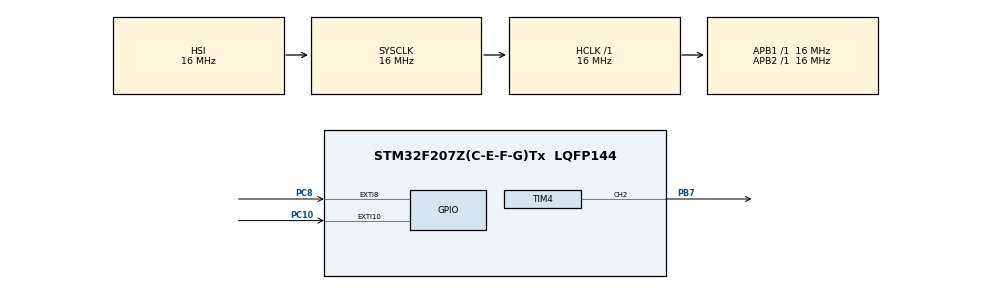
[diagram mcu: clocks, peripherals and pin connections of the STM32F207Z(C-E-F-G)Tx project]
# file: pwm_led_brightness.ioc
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Mcu.Family=STM32F2
Mcu.Name=STM32F207Z(C-E-F-G)Tx
Mcu.Package=LQFP144
NVIC.EXTI15_10_IRQn=true\:0\:0\:false\:false\:true\:true\:true\:true
NVIC.EXTI9_5_IRQn=true\:0\:0\:false\:false\:true\:true\:true\:true
NVIC.PriorityGroup=NVIC_PRIORITYGROUP_4
NVIC.TIM4_IRQn=true\:0\:0\:false\:false\:true\:true\:true\:true
PB7.Signal=S_TIM4_CH2
PC10.GPIO_ModeDefaultEXTI=GPIO_MODE_IT_FALLING
PC10.GPIO_PuPd=GPIO_PULLDOWN
PC10.Signal=GPXTI10
PC8.GPIO_ModeDefaultEXTI=GPIO_MODE_IT_FALLING
PC8.GPIO_PuPd=GPIO_PULLDOWN
PC8.Signal=GPXTI8
PH0-OSC_IN.Mode=HSE-External-Oscillator
PH0-OSC_IN.Signal=RCC_OSC_IN
PH1-OSC_OUT.Mode=HSE-External-Oscillator
PH1-OSC_OUT.Signal=RCC_OSC_OUT
ProjectManager.HeapSize=0x200
ProjectManager.StackSize=0x400
ProjectManager.TargetToolchain=STM32CubeIDE
RCC.48MHZClocksFreq_Value=48000000
RCC.AHBFreq_Value=16000000
RCC.APB1Freq_Value=16000000
RCC.APB2Freq_Value=16000000
RCC.CortexFreq_Value=16000000
RCC.HSE_VALUE=25000000
RCC.HSI_VALUE=16000000
RCC.LSE_VALUE=32768
RCC.SYSCLKFreq_VALUE=16000000
RCC.VCOOutputFreq_Value=192000000
SH.S_TIM4_CH2.0=TIM4_CH2,PWM Generation2 CH2
TIM4.AutoReloadPreload=TIM_AUTORELOAD_PRELOAD_DISABLE
TIM4.Channel-PWM\ Generation2\ CH2=TIM_CHANNEL_2
TIM4.Period=100 - 1
TIM4.Prescaler=1600 - 1
VP_TIM4_VS_ClockSourceINT.Mode=Internal
board=custom

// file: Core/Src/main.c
/* USER CODE BEGIN Header */
/**
  ******************************************************************************
  * @file           : main.c
  * @brief          : Main program body
  ******************************************************************************
  * @attention
  *
  * Copyright (c) 2023 STMicroelectronics.
  * All rights reserved.
  *
  * This software is licensed under terms that can be found in the LICENSE file
  * in the root directory of this software component.
  * If no LICENSE file comes with this software, it is provided AS-IS.
  *
  ******************************************************************************
  */
/* USER CODE END Header */
#include "main.h"

TIM_HandleTypeDef htim4;

/* USER CODE BEGIN PV */
static int pwmValue = 50;
/* USER CODE END PV */

void SystemClock_Config(void);
static void MX_GPIO_Init(void);
static void MX_TIM4_Init(void);

/* USER CODE BEGIN 0 */
void HAL_GPIO_EXTI_Callback(uint16_t GPIO_Pin)
{
	if (GPIO_Pin == GPIO_PIN_8)
	{
		HAL_TIM_PWM_Stop(&htim4, TIM_CHANNEL_2);
		pwmValue -= 5;
		if (pwmValue >= 0)
		{
		TIM4->CCR2 = pwmValue;
		HAL_TIM_PWM_Start(&htim4, TIM_CHANNEL_2);
		}
		else {
			pwmValue = 50;
			HAL_TIM_PWM_Start(&htim4, TIM_CHANNEL_2);
		}
	}
	if (GPIO_Pin == GPIO_PIN_10)
	{
		HAL_TIM_PWM_Stop(&htim4, TIM_CHANNEL_2);
		pwmValue += 5;
		if (pwmValue <= 100)
		{
		TIM4->CCR2 = pwmValue;
		HAL_TIM_PWM_Start(&htim4, TIM_CHANNEL_2);
		}
		else {
			pwmValue = 50;
			HAL_TIM_PWM_Start(&htim4, TIM_CHANNEL_2);
		}
	}
}
/* USER CODE END 0 */

int main(void)
{

  /* MCU Configuration--------------------------------------------------------*/

  /* Reset of all peripherals, Initializes the Flash interface and the Systick. */
  HAL_Init();

  /* Configure the system clock */
  SystemClock_Config();

  /* Initialize all configured peripherals */
  MX_GPIO_Init();
  MX_TIM4_Init();
  /* USER CODE BEGIN 2 */
  if (__HAL_TIM_GET_FLAG(&htim4, TIM_FLAG_UPDATE) != RESET)
	  __HAL_TIM_CLEAR_FLAG(&htim4, TIM_FLAG_UPDATE);
  HAL_TIM_Base_Start_IT(&htim4);
  TIM4->CCR2 = 50;
  HAL_TIM_PWM_Start(&htim4, TIM_CHANNEL_2);
  /* USER CODE END 2 */

  /* Infinite loop */
  while (1)
  {

  }
}

void SystemClock_Config(void)
{
  RCC_OscInitTypeDef RCC_OscInitStruct = {0};
  RCC_ClkInitTypeDef RCC_ClkInitStruct = {0};

  /** Initializes the RCC Oscillators according to the specified parameters
  * in the RCC_OscInitTypeDef structure.
  */
  RCC_OscInitStruct.OscillatorType = RCC_OSCILLATORTYPE_HSI;
  RCC_OscInitStruct.HSIState = RCC_HSI_ON;
  RCC_OscInitStruct.HSICalibrationValue = RCC_HSICALIBRATION_DEFAULT;
  RCC_OscInitStruct.PLL.PLLState = RCC_PLL_NONE;
  if (HAL_RCC_OscConfig(&RCC_OscInitStruct) != HAL_OK)
  {
    Error_Handler();
  }

  /** Initializes the CPU, AHB and APB buses clocks
  */
  RCC_ClkInitStruct.ClockType = RCC_CLOCKTYPE_HCLK|RCC_CLOCKTYPE_SYSCLK
                              |RCC_CLOCKTYPE_PCLK1|RCC_CLOCKTYPE_PCLK2;
  RCC_ClkInitStruct.SYSCLKSource = RCC_SYSCLKSOURCE_HSI;
  RCC_ClkInitStruct.AHBCLKDivider = RCC_SYSCLK_DIV1;
  RCC_ClkInitStruct.APB1CLKDivider = RCC_HCLK_DIV1;
  RCC_ClkInitStruct.APB2CLKDivider = RCC_HCLK_DIV1;

  if (HAL_RCC_ClockConfig(&RCC_ClkInitStruct, FLASH_LATENCY_0) != HAL_OK)
  {
    Error_Handler();
  }
}

static void MX_TIM4_Init(void)
{

  TIM_ClockConfigTypeDef sClockSourceConfig = {0};
  TIM_MasterConfigTypeDef sMasterConfig = {0};
  TIM_OC_InitTypeDef sConfigOC = {0};

  htim4.Instance = TIM4;
  htim4.Init.Prescaler = 1600 - 1;
  htim4.Init.CounterMode = TIM_COUNTERMODE_UP;
  htim4.Init.Period = 100 - 1;
  htim4.Init.ClockDivision = TIM_CLOCKDIVISION_DIV1;
  htim4.Init.AutoReloadPreload = TIM_AUTORELOAD_PRELOAD_DISABLE;
  if (HAL_TIM_Base_Init(&htim4) != HAL_OK)
  {
    Error_Handler();
  }
  sClockSourceConfig.ClockSource = TIM_CLOCKSOURCE_INTERNAL;
  if (HAL_TIM_ConfigClockSource(&htim4, &sClockSourceConfig) != HAL_OK)
  {
    Error_Handler();
  }
  if (HAL_TIM_PWM_Init(&htim4) != HAL_OK)
  {
    Error_Handler();
  }
  sMasterConfig.MasterOutputTrigger = TIM_TRGO_RESET;
  sMasterConfig.MasterSlaveMode = TIM_MASTERSLAVEMODE_DISABLE;
  if (HAL_TIMEx_MasterConfigSynchronization(&htim4, &sMasterConfig) != HAL_OK)
  {
    Error_Handler();
  }
  sConfigOC.OCMode = TIM_OCMODE_PWM1;
  sConfigOC.Pulse = 0;
  sConfigOC.OCPolarity = TIM_OCPOLARITY_HIGH;
  sConfigOC.OCFastMode = TIM_OCFAST_DISABLE;
  if (HAL_TIM_PWM_ConfigChannel(&htim4, &sConfigOC, TIM_CHANNEL_2) != HAL_OK)
  {
    Error_Handler();
  }
  HAL_TIM_MspPostInit(&htim4);

}

static void MX_GPIO_Init(void)
{
  GPIO_InitTypeDef GPIO_InitStruct = {0};

  /* GPIO Ports Clock Enable */
  __HAL_RCC_GPIOH_CLK_ENABLE();
  __HAL_RCC_GPIOC_CLK_ENABLE();
  __HAL_RCC_GPIOB_CLK_ENABLE();

  /*Configure GPIO pins : PC8 PC10 */
  GPIO_InitStruct.Pin = GPIO_PIN_8|GPIO_PIN_10;
  GPIO_InitStruct.Mode = GPIO_MODE_IT_FALLING;
  GPIO_InitStruct.Pull = GPIO_PULLDOWN;
  HAL_GPIO_Init(GPIOC, &GPIO_InitStruct);

  /* EXTI interrupt init*/
  HAL_NVIC_SetPriority(EXTI9_5_IRQn, 0, 0);
  HAL_NVIC_EnableIRQ(EXTI9_5_IRQn);

  HAL_NVIC_SetPriority(EXTI15_10_IRQn, 0, 0);
  HAL_NVIC_EnableIRQ(EXTI15_10_IRQn);

}

void Error_Handler(void)
{
  __disable_irq();
  while (1)
  {
  }
}
